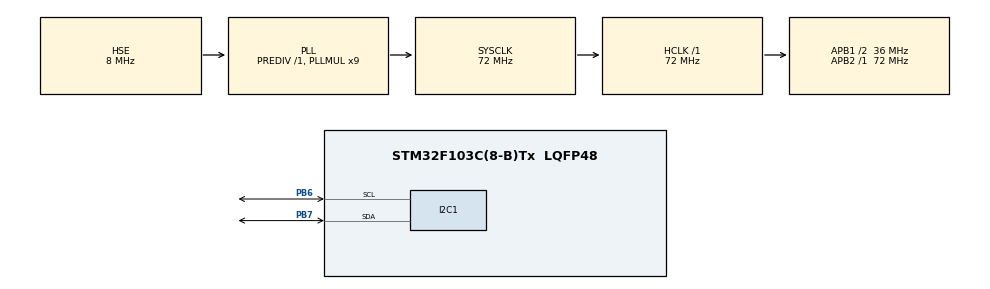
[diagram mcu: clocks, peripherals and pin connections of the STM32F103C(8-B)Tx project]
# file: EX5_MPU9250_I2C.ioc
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Mcu.Family=STM32F1
Mcu.Name=STM32F103C(8-B)Tx
Mcu.Package=LQFP48
NVIC.PriorityGroup=NVIC_PRIORITYGROUP_4
PA13.Mode=Serial_Wire
PA13.Signal=SYS_JTMS-SWDIO
PA14.Mode=Serial_Wire
PA14.Signal=SYS_JTCK-SWCLK
PB6.Mode=I2C
PB6.Signal=I2C1_SCL
PB7.Mode=I2C
PB7.Signal=I2C1_SDA
PD0-OSC_IN.Mode=HSE-External-Oscillator
PD0-OSC_IN.Signal=RCC_OSC_IN
PD1-OSC_OUT.Mode=HSE-External-Oscillator
PD1-OSC_OUT.Signal=RCC_OSC_OUT
ProjectManager.HeapSize=0x200
ProjectManager.StackSize=0x400
ProjectManager.TargetToolchain=STM32CubeIDE
RCC.AHBFreq_Value=72000000
RCC.APB1CLKDivider=RCC_HCLK_DIV2
RCC.APB1Freq_Value=36000000
RCC.APB1TimFreq_Value=72000000
RCC.APB2Freq_Value=72000000
RCC.APB2TimFreq_Value=72000000
RCC.HCLKFreq_Value=72000000
RCC.PLLMUL=RCC_PLL_MUL9
RCC.PLLSourceVirtual=RCC_PLLSOURCE_HSE
RCC.SYSCLKFreq_VALUE=72000000
RCC.SYSCLKSource=RCC_SYSCLKSOURCE_PLLCLK
RCC.USBFreq_Value=72000000
board=custom

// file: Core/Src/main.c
/* USER CODE BEGIN Header */
/**
  ******************************************************************************
  * @file           : main.c
  * @brief          : Main program body
  ******************************************************************************
  *						 EXEMPLO DE MPU9250 (stm32f103c8)
  ******************************************************************************
  * Aluno:        Ruan Robert Bispo dos Santos                            2019.2
  * Orientadores: Lucas Molina e Elyson Adan Nunes Carvalho
  *
  * CODIGO DA PLACA DE INTERFACE DO MATLAB COM O STM32F103C8
  *
  * @Resumo: Código teste para o MPU9250. Nesse exemplo é implementada um
  *          exemplo de coleta de dados da unidade inercial de medida mpu9250
  *          Esse código também pode ser utilizado para uso na mpu6050, uma vez
  *          que a única diferença é que não possui o módulo magnetômetro AK8963
  *
  * @Configurações:
  *   		 Clock   - 72 MHz
  *   		 I2C     - i2c1
  *
  * @Bibliotecas:
  * 		 Comunicação com sensor MPU9250    - biblioteca "sd_hal_mpu9250.h"
  *
  ******************************************************************************
  * @attention
  *
  * <h2><center>&copy; Copyright (c) 2020 STMicroelectronics.
  * All rights reserved.</center></h2>
  *
  * This software component is licensed by ST under BSD 3-Clause license,
  * the "License"; You may not use this file except in compliance with the
  * License. You may obtain a copy of the License at:
  *                        opensource.org/licenses/BSD-3-Clause
  *
  ******************************************************************************
  */
/* USER CODE END Header */

#include "main.h"

/* USER CODE BEGIN Includes */
#include "sd_hal_mpu9250.h"

/* USER CODE END Includes */

I2C_HandleTypeDef hi2c1;

/* USER CODE BEGIN PV */

// IMU MPU9250
SD_MPU6050 mpu1;
float temper = 0;
float g_x = 0;
float g_y = 0;
float g_z = 0;
float a_x = 0;
float a_y = 0;
float a_z = 0;
float m_x = 0;
float m_y = 0;
float m_z = 0;
float gRes = 250.0/32768.0; //cte de transformação
float aRes = 2.0/32768.0;   //cte de transformação
float mRes = 10.0*4912.0/8190.0; //cte de transformação
float magCalibrate[3] = {0, 0, 0}, magBias[3] = {0, 0, 0};
float gyroBias[3] = {0, 0, 0}, accelBias[3] = {0, 0, 0};

/* USER CODE END PV */

void SystemClock_Config(void);
static void MX_GPIO_Init(void);
static void MX_I2C1_Init(void);

int main(void)
{

  /* MCU Configuration--------------------------------------------------------*/

  /* Reset of all peripherals, Initializes the Flash interface and the Systick. */
  HAL_Init();

  /* Configure the system clock */
  SystemClock_Config();

  /* Initialize all configured peripherals */
  MX_GPIO_Init();
  MX_I2C1_Init();
  /* USER CODE BEGIN 2 */

    // inicialização do MPU9250: MPU6050(Accel & Gyro) e AK8963(Magnetometer)
	SD_MPU6050_Init(&hi2c1,&mpu1,SD_MPU6050_Device_0,SD_MPU6050_Accelerometer_2G,SD_MPU6050_Gyroscope_250s );
	HAL_Delay(5);
	initAK8963(&hi2c1,magCalibrate);
	HAL_Delay(5);

  /* USER CODE END 2 */

  /* Infinite loop */
  /* USER CODE BEGIN WHILE */
  while (1)
  {
	  ////////////////////////////////////////////////////////
	  // MPU9250 *******************************************//

	  SD_MPU6050_ReadAll(&hi2c1,&mpu1);
	  SD_MPU9250_ReadMagnetometer(&hi2c1,&mpu1);
	  g_x = gRes*mpu1.Gyroscope_X - gyroBias[0];
	  g_y = gRes*mpu1.Gyroscope_Y - gyroBias[1];
	  g_z = gRes*mpu1.Gyroscope_Z - gyroBias[2];
	  a_x = aRes*mpu1.Accelerometer_X - accelBias[0];
	  a_y = aRes*mpu1.Accelerometer_Y - accelBias[1];
	  a_z = aRes*mpu1.Accelerometer_Z - accelBias[2];
	  m_x = mRes*mpu1.Magnetometer_X*magCalibrate[0] - magBias[0];
	  m_y = mRes*mpu1.Magnetometer_Y*magCalibrate[1] - magBias[1];
	  m_z = mRes*mpu1.Magnetometer_Z*magCalibrate[2] - magBias[2];

	  /////////////////////////////////////////////////////////
	  // Nota: Caso deseje ajustar o bias dos sensores basta
	  // atualizar com as variáveis de bias já descritas acima

    /* USER CODE END WHILE */

  }
}

void SystemClock_Config(void)
{
  RCC_OscInitTypeDef RCC_OscInitStruct = {0};
  RCC_ClkInitTypeDef RCC_ClkInitStruct = {0};

  /** Initializes the CPU, AHB and APB busses clocks
  */
  RCC_OscInitStruct.OscillatorType = RCC_OSCILLATORTYPE_HSE;
  RCC_OscInitStruct.HSEState = RCC_HSE_ON;
  RCC_OscInitStruct.HSEPredivValue = RCC_HSE_PREDIV_DIV1;
  RCC_OscInitStruct.HSIState = RCC_HSI_ON;
  RCC_OscInitStruct.PLL.PLLState = RCC_PLL_ON;
  RCC_OscInitStruct.PLL.PLLSource = RCC_PLLSOURCE_HSE;
  RCC_OscInitStruct.PLL.PLLMUL = RCC_PLL_MUL9;
  if (HAL_RCC_OscConfig(&RCC_OscInitStruct) != HAL_OK)
  {
    Error_Handler();
  }
  /** Initializes the CPU, AHB and APB busses clocks
  */
  RCC_ClkInitStruct.ClockType = RCC_CLOCKTYPE_HCLK|RCC_CLOCKTYPE_SYSCLK
                              |RCC_CLOCKTYPE_PCLK1|RCC_CLOCKTYPE_PCLK2;
  RCC_ClkInitStruct.SYSCLKSource = RCC_SYSCLKSOURCE_PLLCLK;
  RCC_ClkInitStruct.AHBCLKDivider = RCC_SYSCLK_DIV1;
  RCC_ClkInitStruct.APB1CLKDivider = RCC_HCLK_DIV2;
  RCC_ClkInitStruct.APB2CLKDivider = RCC_HCLK_DIV1;

  if (HAL_RCC_ClockConfig(&RCC_ClkInitStruct, FLASH_LATENCY_2) != HAL_OK)
  {
    Error_Handler();
  }
}

static void MX_I2C1_Init(void)
{

  hi2c1.Instance = I2C1;
  hi2c1.Init.ClockSpeed = 100000;
  hi2c1.Init.DutyCycle = I2C_DUTYCYCLE_2;
  hi2c1.Init.OwnAddress1 = 0;
  hi2c1.Init.AddressingMode = I2C_ADDRESSINGMODE_7BIT;
  hi2c1.Init.DualAddressMode = I2C_DUALADDRESS_DISABLE;
  hi2c1.Init.OwnAddress2 = 0;
  hi2c1.Init.GeneralCallMode = I2C_GENERALCALL_DISABLE;
  hi2c1.Init.NoStretchMode = I2C_NOSTRETCH_DISABLE;
  if (HAL_I2C_Init(&hi2c1) != HAL_OK)
  {
    Error_Handler();
  }

}

static void MX_GPIO_Init(void)
{

  /* GPIO Ports Clock Enable */
  __HAL_RCC_GPIOD_CLK_ENABLE();
  __HAL_RCC_GPIOA_CLK_ENABLE();
  __HAL_RCC_GPIOB_CLK_ENABLE();

}

void Error_Handler(void)
{
}

/************************ (C) COPYRIGHT STMicroelectronics *****END OF FILE****/
